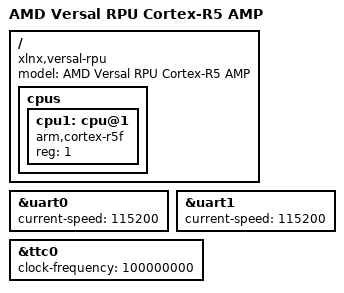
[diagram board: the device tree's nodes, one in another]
/*
 * Copyright (c) 2026, Advanced Micro Devices, Inc.
 *
 * SPDX-License-Identifier: Apache-2.0
 *
 * Base DTS for Versal RPU AMP (split-mode).
 * Adds cpu@1 and enables both UARTs for dual-core operation.
 * Sub-variants core0/core1 select their own memory and console.
 */

/dts-v1/;
#include <arm/xilinx/versal_rpu.dtsi>

/ {
	model = "AMD Versal RPU Cortex-R5 AMP";
	compatible = "xlnx,versal-rpu";

	cpus {
		cpu1: cpu@1 {
			device_type = "cpu";
			compatible = "arm,cortex-r5f";
			reg = <1>;
		};
	};
};

&uart0 {
	status = "okay";
	current-speed = <115200>;
};

&uart1 {
	status = "okay";
	current-speed = <115200>;
};

&ttc0 {
	status = "okay";
	clock-frequency = <100000000>;
};
